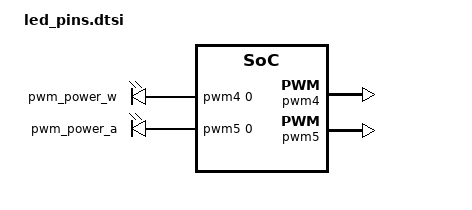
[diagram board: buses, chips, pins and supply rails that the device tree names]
/* Copyright 2024 The ChromiumOS Authors
 * Use of this source code is governed by a BSD-style license that can be
 * found in the LICENSE file.
 */

/ {
	pwmleds {
		compatible = "pwm-leds";

		pwm_power_w: pwm_power_w {
			pwms = <&pwm4 0 PWM_HZ(324) PWM_POLARITY_NORMAL>;
		};

		pwm_power_a: pwm_power_a {
			pwms = <&pwm5 0 PWM_HZ(324) PWM_POLARITY_NORMAL>;
		};
	};

	pwm-led-pins {
		compatible = "cros-ec,pwm-led-pins";

		power_led: power-led {
			/* The first power led on the power button module */
			led-id = "EC_LED_ID_POWER_LED";
			led-pwms = <&pwm_power_w>;

			color_power_off: color-power-off {
				led-color = "LED_OFF";
				led-values = <0>;
			};

			color_power_white: color-power-white {
				led-color = "LED_WHITE";
				/* maximum duty */
				led-values = <55>;
			};
		};

		chassis_led3: chassis-led3 {
			/* The second power led on the mainboard */
			led-id = "EC_LED_ID_SECOND_POWER_LED";
			led-pwms = <&pwm_power_a>;

			color_led3_off: color-led3-off {
				led-color = "LED_OFF";
				led-values = <0>;
			};

			color_led3_amber: color-led3-amber {
				led-color = "LED_AMBER";
				/* maximum duty */
				led-values = <55>;
			};
		};
	};
};

/* POWER LED */
&pwm4 {
	status = "okay";
	clock-bus = "NPCX_CLOCK_BUS_LFCLK";
	pinctrl-0 = <&pwm4_gpb6>;
	pinctrl-names = "default";
};

/* LED3_DRV_PWM */
&pwm5 {
	status = "okay";
	clock-bus = "NPCX_CLOCK_BUS_LFCLK";
	pinctrl-0 = <&pwm5_gpb7>;
	pinctrl-names = "default";
};
